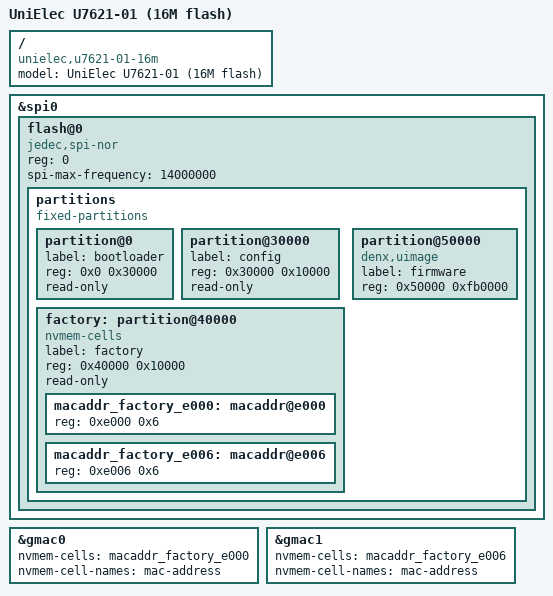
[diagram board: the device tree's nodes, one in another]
// SPDX-License-Identifier: GPL-2.0-or-later OR MIT

#include "mt7621_unielec_u7621-01.dtsi"

/ {
	compatible = "unielec,u7621-01-16m", "unielec,u7621-01", "mediatek,mt7621-soc";
	model = "UniElec U7621-01 (16M flash)";
};

&spi0 {
	status = "okay";

	flash@0 {
		compatible = "jedec,spi-nor";
		reg = <0>;
		spi-max-frequency = <14000000>;

		partitions {
			compatible = "fixed-partitions";
			#address-cells = <1>;
			#size-cells = <1>;

			partition@0 {
				label = "bootloader";
				reg = <0x0 0x30000>;
				read-only;
			};

			partition@30000 {
				label = "config";
				reg = <0x30000 0x10000>;
				read-only;
			};

			factory: partition@40000 {
				label = "factory";
				reg = <0x40000 0x10000>;
				read-only;
			};

			partition@50000 {
				compatible = "denx,uimage";
				label = "firmware";
				reg = <0x50000 0xfb0000>;
			};
		};
	};
};

&gmac0 {
	nvmem-cells = <&macaddr_factory_e000>;
	nvmem-cell-names = "mac-address";
};

&gmac1 {
	nvmem-cells = <&macaddr_factory_e006>;
	nvmem-cell-names = "mac-address";
};

&factory {
	compatible = "nvmem-cells";
	#address-cells = <1>;
	#size-cells = <1>;

	macaddr_factory_e000: macaddr@e000 {
		reg = <0xe000 0x6>;
	};

	macaddr_factory_e006: macaddr@e006 {
		reg = <0xe006 0x6>;
	};
};
